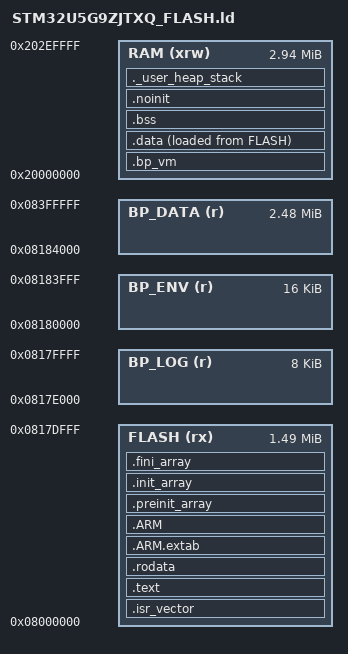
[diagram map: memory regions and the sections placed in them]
/*
******************************************************************************
**
** @file        : LinkerScript.ld
**
** @author      : Auto-generated by STM32CubeIDE
**
**  Abstract    : Linker script for STM32U5G9J-DK2 Board embedding STM32U5G9ZJTxQ Device from stm32u5 series
**                      4096KBytes FLASH
**                      3008KBytes RAM
**
**                Set heap size, stack size and stack location according
**                to application requirements.
**
**                Set memory bank area and size if external memory is used
**
**  Target      : STMicroelectronics STM32
**
**  Distribution: The file is distributed as is, without any warranty
**                of any kind.
**
******************************************************************************
** @attention
**
** Copyright (c) 2026 STMicroelectronics.
** All rights reserved.
**
** This software is licensed under terms that can be found in the LICENSE file
** in the root directory of this software component.
** If no LICENSE file comes with this software, it is provided AS-IS.
**
******************************************************************************
*/

/* Entry Point */
ENTRY(Reset_Handler)

/* Highest address of the user mode stack */
_estack = ORIGIN(RAM) + LENGTH(RAM); /* end of "RAM" Ram type memory */
_sstack = _estack - _Min_Stack_Size;

_Min_Heap_Size = 0x200; /* required amount of heap */
_Min_Stack_Size = 0x1000; /* 4 KB, como la Nucleo. Eran 16 KB desde V3/H5.0, cuando el interprete BP corria sobre
                             este stack; desde A1.5 corre en la tarea `vm` y el MSP solo lo usan las interrupciones:
                             medidos <= 272 B con la GUI, el tactil y el wire (V7/H7, 30-sep, la linea `mem:`). */

/* Memories definition */
MEMORY
{
  RAM    (xrw)    : ORIGIN = 0x20000000,   LENGTH = 3008K
  FLASH    (rx)    : ORIGIN = 0x08000000,   LENGTH = 1528K
  BP_LOG   (r)    : ORIGIN = 0x0817E000,   LENGTH = 8K
  BP_ENV   (r)    : ORIGIN = 0x08180000,   LENGTH = 16K
  BP_DATA  (r)    : ORIGIN = 0x08184000,   LENGTH = 2544K
}

/* H9 — layout por capas (Eduardo): [firmware][log][env A/B][datos FS+Packs].
 *   FLASH   1528K -> firmware (LVGL + VM). El enlazador SOLO coloca secciones aqui.
 *   BP_LOG     8K -> log persistente (1 pagina), SIN secciones.
 *   BP_ENV    16K -> env A/B (2 paginas de 8K), SIN secciones.
 *   BP_DATA 2544K -> datos FS+Packs (el env reparte FS|Packs), SIN secciones.
 * BP_LOG/BP_ENV/BP_DATA sin secciones -> el flasheo no los graba -> sobreviven al
 * reflasheo. El FS viejo @0x08380000 queda subsumido en BP_DATA. Cuadran con
 * flash_layout_stm32.h (rama DK2). */
__bp_flash_end  = ORIGIN(FLASH) + LENGTH(FLASH);   /* 0x0817E000 (fin del codigo; el log ocupa la pagina siguiente) */
__bp_log_start  = ORIGIN(BP_LOG);                  /* 0x0817E000 (sector del log persistente) */
__bp_part_start = ORIGIN(BP_DATA);                 /* 0x08184000 */
__bp_ram_start  = ORIGIN(RAM);                     /* 0x20000000 — V7/H6 G5.b0: donde tiene que empezar la VM (.bp_vm) */

/* Sections */
SECTIONS
{

  /* The startup code into "FLASH" Rom type memory */
  .isr_vector :
  {
    . = ALIGN(4);
    KEEP(*(.isr_vector)) /* Startup code */
    . = ALIGN(4);
  } >FLASH

  /* The program code and other data into "FLASH" Rom type memory */
  .text :
  {
    . = ALIGN(4);
    *(.text)           /* .text sections (code) */
    *(.text*)          /* .text* sections (code) */
    *(.glue_7)         /* glue arm to thumb code */
    *(.glue_7t)        /* glue thumb to arm code */
    *(.eh_frame)

    KEEP (*(.init))
    KEEP (*(.fini))

    . = ALIGN(4);
    _etext = .;        /* define a global symbols at end of code */
  } >FLASH

  /* Constant data into "FLASH" Rom type memory */
  .rodata :
  {
    . = ALIGN(4);
    *(.rodata)         /* .rodata sections (constants, strings, etc.) */
    *(.rodata*)        /* .rodata* sections (constants, strings, etc.) */
    . = ALIGN(4);
  } >FLASH

  .ARM.extab (READONLY) : /* The "READONLY" keyword is only supported in GCC11 and later, remove it if using GCC10 or earlier. */
  {
    . = ALIGN(4);
    *(.ARM.extab* .gnu.linkonce.armextab.*)
    . = ALIGN(4);
  } >FLASH

  .ARM (READONLY) : /* The "READONLY" keyword is only supported in GCC11 and later, remove it if using GCC10 or earlier. */
  {
    . = ALIGN(4);
    __exidx_start = .;
    *(.ARM.exidx*)
    __exidx_end = .;
    . = ALIGN(4);
  } >FLASH

  .preinit_array (READONLY) : /* The "READONLY" keyword is only supported in GCC11 and later, remove it if using GCC10 or earlier. */
  {
    . = ALIGN(4);
    PROVIDE_HIDDEN (__preinit_array_start = .);
    KEEP (*(.preinit_array*))
    PROVIDE_HIDDEN (__preinit_array_end = .);
    . = ALIGN(4);
  } >FLASH

  .init_array (READONLY) : /* The "READONLY" keyword is only supported in GCC11 and later, remove it if using GCC10 or earlier. */
  {
    . = ALIGN(4);
    PROVIDE_HIDDEN (__init_array_start = .);
    KEEP (*(SORT(.init_array.*)))
    KEEP (*(.init_array*))
    PROVIDE_HIDDEN (__init_array_end = .);
    . = ALIGN(4);
  } >FLASH

  .fini_array (READONLY) : /* The "READONLY" keyword is only supported in GCC11 and later, remove it if using GCC10 or earlier. */
  {
    . = ALIGN(4);
    PROVIDE_HIDDEN (__fini_array_start = .);
    KEEP (*(SORT(.fini_array.*)))
    KEEP (*(.fini_array*))
    PROVIDE_HIDDEN (__fini_array_end = .);
    . = ALIGN(4);
  } >FLASH

  /* V7/H6 G5.b0 (26-sep) — LA MEMORIA DE LA VM, LO PRIMERO DE LA RAM.
   *
   * `s_vm_mem` (stm32_repl.c, seccion `.bss.bp_vm`) va aqui y no en la `.bss` para
   * que su direccion sea SIEMPRE ORIGIN(RAM), cambie lo que cambie el resto de la
   * imagen: del principio de ese array sale el bloque de RAM de los packs nativos
   * (`packRam=` del ENV), y los motores grabados llevan esa direccion en su SELLO.
   * En la `.bss` se movia con cada enlace, y cada imagen nueva habria obligado a
   * regrabar los packs.
   *
   * NOLOAD y fuera de _sbss.._ebss: el arranque no la pone a cero, y no hace falta
   * (bpvm_init no lo supone, y cada RUN ya reutiliza el mismo bufer). Tiene que ir
   * ANTES que `.data`: el enlazador reparte la region en el orden del guion, y un
   * `*(.bss.bp_vm)` aqui se queda la seccion antes que el `*(.bss*)` de la `.bss`.
   * El arranque comprueba `__bp_vm_start == __bp_ram_start` y, si no, no hay
   * bloque para los motores (y lo dice).
   *
   * ATENCION: este .ld lo genera CubeIDE (ver la nota de `.noinit`): si se regenera,
   * hay que volver a poner esto — y no se callaria: sin `__bp_vm_start` no enlaza.
   */
  .bp_vm (NOLOAD) :
  {
    . = ALIGN(8);
    __bp_vm_start = .;
    *(.bss.bp_vm)
    . = ALIGN(8);
    __bp_vm_end = .;
  } >RAM

  /* Used by the startup to initialize data */
  _sidata = LOADADDR(.data);

  /* Initialized data sections into "RAM" Ram type memory */
  .data :
  {
    . = ALIGN(4);
    _sdata = .;        /* create a global symbol at data start */
    *(.data)           /* .data sections */
    *(.data*)          /* .data* sections */
    *(.RamFunc)        /* .RamFunc sections */
    *(.RamFunc*)       /* .RamFunc* sections */

    . = ALIGN(4);
    _edata = .;        /* define a global symbol at data end */

  } >RAM AT> FLASH

  /* Uninitialized data section into "RAM" Ram type memory */
  . = ALIGN(4);
  .bss :
  {
    /* This is used by the startup in order to initialize the .bss section */
    _sbss = .;         /* define a global symbol at bss start */
    __bss_start__ = _sbss;
    *(.bss)
    *(.bss*)
    *(COMMON)

    . = ALIGN(4);
    _ebss = .;         /* define a global symbol at bss end */
    __bss_end__ = _ebss;
  } >RAM

  /* #439 — SECCION QUE EL ARRANQUE NO BORRA.
   *
   * El log post-mortem vive aqui para que sobreviva al reset: el startup solo
   * limpia de _sbss a _ebss, asi que lo que caiga FUERA de ese rango llega
   * intacto. Gemelo de `__uninitialized_ram` (Pico) y `__NOINIT_ATTR` (ESP32).
   *
   * ATENCION: este .ld lo genera CubeIDE. Si algun dia se regenera el proyecto
   * hay que volver a poner esto — y se notara porque el log dejara de
   * sobrevivir, en silencio. Comprobacion: `arm-none-eabi-objdump -h` tiene que
   * enseñar `.noinit` con ALLOC y SIN LOAD, y el simbolo del log dentro.
   */
  .noinit (NOLOAD) :
  {
    . = ALIGN(4);
    *(.noinit)
    *(.noinit*)
    . = ALIGN(4);
  } >RAM

  /* User_heap_stack section, used to check that there is enough "RAM" Ram  type memory left */
  ._user_heap_stack :
  {
    . = ALIGN(8);
    PROVIDE ( end = . );
    PROVIDE ( _end = . );
    . = . + _Min_Heap_Size;
    . = . + _Min_Stack_Size;
    . = ALIGN(8);
  } >RAM

  /* Remove information from the compiler libraries */
  /DISCARD/ :
  {
    libc.a ( * )
    libm.a ( * )
    libgcc.a ( * )
  }

  .ARM.attributes 0 : { *(.ARM.attributes) }
}
